# SF32LB57x register map
File version: 1.0
CPU: CM33 r0p1, little endian, MPU, FPU, 3 interrupt priority bits
Registers are 32-bit, read-write, reset 0x0 unless marked. A register's access mark holds for its fields unless they carry their own. Offsets are from the block's base; [hi:lo] are bit positions; {n}, {i} and the like mark numbered series.

## CAN1
Base 0x5000A000
Same registers: CAN2 0x5000E000
0x00 RBUF — Receive Buffer Registers
  [31:0] DATA
0x48 TBUF — Transmit Buffer Registers
  [31:0] DATA
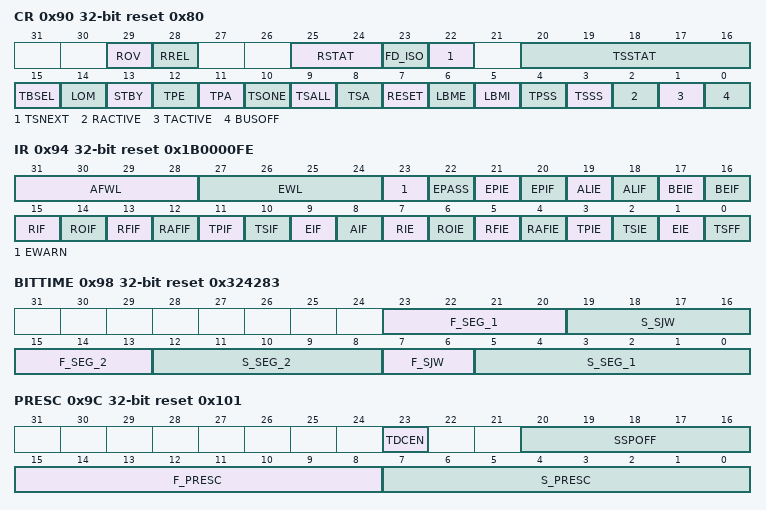
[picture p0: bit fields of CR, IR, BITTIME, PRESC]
0x90 CR reset 0x80 — Control Register
  [29] ROV — Receive buffer OVerflow 1 – Overflow. At least one message is lost. 0 – No Overflow. ROV is cleared by setting RREL=1.
  [28] RREL — Receive buffer RELease The host controller acknowledges the emptying of the actual RB slot. Afterwards the CAN-CTRL core points to the next RB slot. RSTAT gets updated. 1 – Release: The host has emptied the RB. 0 – No release
  [25:24] RSTAT — Receive buffer STATus 00 - empty 01 - > empty and lt almost full (AFWL) 10 - >= almost full (programmable threshold by AFWL) but not full and no overflow 11 - full (stays set in case of overflow – for overflow signaling see ROV)
  [23] FD_ISO — CAN FD ISO mode 0 - Bosch CAN FD (non-ISO) mode 1 - ISO CAN FD mode This bit is only writeable if RESET=1. ISO CAN FD mode has a different CRC initialization value and an additional stuff bit count. Both modes are incompatible and must not be mixed in one CAN network. This bit has no impact to CAN 2.0B.
  [22] TSNEXT — Transmit buffer Secondary NEXT 0 - no action 1 - STB slot filled, select next FIFO slot. After all frame bytes are written to the TBUF registers, the host controller has to set TSNEXT to signal that this slot has been filled. Then the CAN-CTRL core connects the TBUF registers to the next FIFO slot. Once a slot is marked as filled a transmission can be started using TSONE or TSALL. TSNEXT has to be set by the host controller and is automatically reset by the CAN-CTRL core immediately after it was set. Setting TSNEXT is only meaningful, if the STB is selected by TBSEL=1. If TBSEL=0 then TSNEXT is ignored and automatically cleared. It does not do any harm. If all slots of the STB are filled, TSNEXT stays set until a slot becomes free (chap. 3.6.7 ).
  [20:16] TSSTAT — Transmission Secondary STATus bits Number of filled message buffers (0 …16).
  [15] TBSEL — Transmit Buffer Select Selects the transmit buffer to be loaded with a message. Use the TBUF registers for access. TBSEL needs to be stable all the time the TBUF registers are written and when TSNEXT is set. 0 - PTB (high-priority buffer) 1 - STB (FIFO like)
  [14] LOM — Listen Only Mode 0 - Disabled 1 - Enabled LOM should not be enabled while a transmission is active. No transmission can be started if LOM is enabled.
  [13] STBY — Transceiver Standby Mode 0 - Disabled 1 - Enabled This register bit is connected to the output signal stby which can be used to control a standby mode of a transceiver. STBY cannot be set to 1 if TPE=1, TSONE=1 or TSALL=1. If the host sets STBY to 0 then the host needs to wait for the time required by the transceiver to start up before the host requests a new transmission.
  [12] TPE — Transmit Primary Enable 1 - Transmission enable of the message of the high-priority PTB 0 - No transmission for the PTB If TPE is set, the message from the PTB will be transmitted at the next possible transmit position. A started transmission from the STB will be completed before, but pending new messages are delayed until the PTB message has been transmitted. TPE stays set until the message has been transmitted successfully or it is aborted using TPA. Only, the host controller can set TPE. The host controller can set TPE to 1 but can not reset it to 0. This would only be possible using TPA and aborting the message. During the short time while the CAN-CTRL core resets the bit, it cannot be set by the host. The bit will be reset to the hardware reset value if RESET=1, BUSOFF=1, STBY=1 or LOM=1.
  [11] TPA — Transmit Primary Abort 1 – Aborts a transmission from TPB which has been requested by TPE=1 but not started yet. (The data bytes of the message remain in the PTB.) 0 – no abort The bit has to be set by the host controller and will be reset by CAN-CTRL. Setting TPA automatically de-asserts TPE. The host controller can set TPA to 1 but can not reset it to 0. During the short time while the CAN-CTRL core resets the bit, it cannot be set by the host. The bit will be reset to the hardware reset value if RESET=1 or BUSOFF=1. TPA should not be set simultaneously with TPE.
  [10] TSONE — Transmit Secondary ONE frame 1 – Transmission enable of the oldest message in the STB. The message format is stored in the IDE buffer which belongs to this message. The controller starts the transmission as soon as the bus becomes vacant and no request of the PTB (bit TPE) is pending. 0 – No transmission for the STB. TSONE stays set until the message has been transmitted successfully or it is aborted using TSA. Only the host controller can set TSONE. The host controller can set TSONE to 1 but can not reset it to 0. This would only be possible using TSA and aborting the message. During the short time while the CAN-CTRL core resets the bit, it cannot be set by the host. The bit will be reset to the hardware reset value if RESET=1, BUSOFF=1, STBY=1 or LOM=1.
  [9] TSALL — Transmit Secondary ALL frames 1 – Transmission enable of all messages in the STB. The message format is stored in the appropriate IDE buffers. The controller starts the transmission as soon as the bus becomes vacant and no request of the PTB (bit TPE) is pending. 0 – No transmission for the STB. TSALL stays set until all messages have been transmitted successfully or they are aborted using TSA. Only the host controller can set TSALL. The host controller can set TSALL to 1 but can not reset it to 0. This would only be possible using TSA and aborting the messages. During the short time while the CAN-CTRL core resets the bit, it cannot be set by the host. The bit will be reset to the hardware reset value if RESET=1, BUSOFF=1, STBY=1 or LOM=1. If during a transmission the STB is loaded with a new frame then the new frame will be transmitted too. In other words: a transmission initiated by TSALL is finished when the STB becomes empty. TSALL cannot ne set to 1 if STBY=1.
  [8] TSA — Transmit Secondary Abort 1 – Aborts a transmission from STB which has been requested but not started yet. For a TSONE transmission, only one frame is aborted while for a TSALL Transmission, all frames are aborted. One or all message slots will be released which updates TSSTAT. Because of the FIFO-like behavior of the STB all aborted messages are lost because they are not accessible any more. 0 – no abort The bit has to be set by the host controller and will be reset by CAN-CTRL. Setting TSA, automatically de-asserts TSONE or TSALL respectively. The host controller can set TSA to 1 but can not reset it to 0. The bit will be reset to the hardware reset value if RESET=1 or BUSOFF=1. TSA should not be set simultaneously with TSONE or TSALL.
  [7] RESET — RESET request bit 1 - The host controller performs a local reset of CAN-CTRL. 0 - no local reset of CAN-CTRL The node configuration (BITTIME_x, x_PRESC, acceptance code and mask) can only be modified if RESET=1. The CAN-CTRL core continuously listens on the bus. Wrong timings and acceptance filters may result in unpredictable and unwanted behavior. Therefore these parameters can only be changed if the protocol machine is reset and therefore disconnected from the bus. Bit RESET forces several components to a reset state. A detailed definition is given in chap. 3.6.10 . RESET is automatically set if the node enters “bus off” state (chap. 3.6.1 ). Note that a CAN node will participate in CAN communication after RESET is switched to 0 after 11 CAN bit times. This delay is required by the CAN standard. If RESET is set to 1 and immediately set to 0, then it takes some time until RESET can be read as 0 and becomes inactive. The reason is clock domain crossing from host to CAN clock domain. RESET is held active as long as needed depending on the relation between host and CAN clock.
  [6] LBME — Loop Back Mode, External 0 - Disabled 1 - Enabled LBME should not be enabled while a transmission is active.
  [5] LBMI — Loop Back Mode, Internal 0 - Disabled 1 - Enabled LBMI should not be enabled while a transmission is active.
  [4] TPSS — Transmission Primary Single Shot mode for PTB 0 - Disabled 1 - Enabled
  [3] TSSS — Transmission Secondary Single Shot mode for STB 0 - Disabled 1 - Enabled
  [2] RACTIVE — Reception ACTIVE (Receive Status bit) 1 - The controller is presently receiving data or a remote frame. 0 - No receive activity.
  [1] TACTIVE — Transmission ACTIVE (Transmit Status bit) 1 - The controller is presently transmitting data or a remote frame. 0 - No transmit activity.
  [0] BUSOFF — Bus Off (Bus Status bit) 1 - The controller status is “bus off”. 0 - The controller status is “bus on”.
0x94 IR reset 0x1B0000FE — Interrupt register
  [31:28] AFWL — receive buffer Almost Full Warning Limit AFWL defines the internal warning limit AFWL_i with nRB being the number of available RB slots.
  [27:24] EWL — Programmable Error Warning Limit = (EWL+1)*8. Possible Limit values: 8, 16, … 128. The value of EWL controls EIF. EWL needs to be transferred using CDC from host to CAN clock domain. During transfer EWL register bits are write-locked for the host for a few clocks until CDC is complete.
  [23] EWARN — Error WARNing limit reached 1 - One of the error counters RECNT or TECNT is equal or bigger than EWL 0 - The values in both counters are less than EWL.
  [22] EPASS — Error Passive mode active 0 - not active (node is error active) 1 - active (node is error passive)
  [21] EPIE — Error Passive Interrupt Enable
  [20] EPIF — Error Passive Interrupt Flag. EPIF will be activated if the error status changes from error active to error passive or vice versa and if this interrupt is enabled.
  [19] ALIE — Arbitration Lost Interrupt Enable
  [18] ALIF — Arbitration Lost Interrupt Flag
  [17] BEIE — Bus Error Interrupt Enable
  [16] BEIF — Bus Error Interrupt Flag
  [15] RIF — Receive Interrupt Flag 1 - Data or a remote frame has been received and is available in the receive buffer. 0 - No frame has been received.
  [14] ROIF — RB Overrun Interrupt Flag 1 - At least one received message has been overwritten in the RB. 0 - No RB overwritten. In case of an overrun both ROIF and RFIF will be set.
  [13] RFIF — RB Full Interrupt Flag 1 - All RBs are full. If no RB will be released until the next valid message is received, the oldest message will be lost. 0 - The RB FIFO is not full.
  [12] RAFIF — RB Almost Full Interrupt Flag 1 - number of filled RB slots >= AFWL_i 0 - number of filled RB slots lt AFWL_i
  [11] TPIF — Transmission Primary Interrupt Flag 1 - The requested transmission of the PTB has been successfully completed. 0 - No transmission of the PTB has been completed.
  [10] TSIF — Transmission Secondary Interrupt Flag 1 - The requested transmission of the STB has been successfully completed. 0 - No transmission of the STB has been completed successfully.
  [9] EIF — Error Interrupt Flag 1 - The border of the error warning limit has been crossed in either direction, or the BUSOFF bit has been changed in either direction. 0 - There has been no change.
  [8] AIF — Abort Interrupt Flag 1 - After setting TPA or TSA the appropriated message(s) have been aborted. It is recommended to not set both TPA and TSA simultaneously because both source AIF. 0 - No abort has been executed. The AIF does not have an associated enable register.
  [7] RIE — Receive Interrupt Enable 0 – Disabled, 1 – Enabled
  [6] ROIE — RB Overrun Interrupt Enable 0 – Disabled, 1 – Enabled
  [5] RFIE — RB Full Interrupt Enable 0 – Disabled, 1 – Enabled
  [4] RAFIE — RB Almost Full Interrupt Enable 0 – Disabled, 1 – Enabled
  [3] TPIE — Transmission Primary Interrupt Enable 0 – Disabled, 1 – Enabled
  [2] TSIE — Transmission Secondary Interrupt Enable 0 – Disabled, 1 – Enabled
  [1] EIE — Error Interrupt Enable 0 – Disabled, 1 – Enabled
  [0] TSFF — Transmit Secondary buffer Full Flag 1 - The STB is filled with the maximal count of messages. 0 - The STB is not filled with the maximal count of messages
0x98 BITTIME reset 0x324283
  [23:20] F_SEG_1 — Bit Timing Segment 1 (fast speed) The sample point will be set to tSeg_1=(Seg_1+2)*TQ after start of bit time. Seg_1=0 is meaningless and automatically treated as 1.
  [19:16] S_SJW — Synchronization Jump Width (slow speed) The Synchronization Jump Width tSJW=(SJW+1)*TQ is the maximum time for shortening or lengthening the Bit Time for resynchronization, where TQ is a time quanta.
  [15:13] F_SEG_2 — Bit Timing Segment 2 (fast speed) Time tSeg_2=(Seg_2+1)*TQ after the sample point. Seg_2=0 is meaningless and automatically treated as 1.
  [12:8] S_SEG_2 — Bit Timing Segment 2 (slow speed) Time tSeg_2=(Seg_2+1)*TQ after the sample point. Seg_2=0 is meaningless and automatically treated as 1.
  [7:6] F_SJW — Synchronization Jump Width (fast speed) The Synchronization Jump Width tSJW=(SJW+1)*TQ is the maximum time for shortening or lengthening the Bit Time for resynchronization, where TQ is a time quanta.
  [5:0] S_SEG_1 — Bit Timing Segment 1 (slow speed) The sample point will be set to tSeg_1=(Seg_1+2)*TQ after start of bit time. Seg_1=0 is meaningless and automatically treated as 1.
0x9C PRESC reset 0x101
  [23] TDCEN — Transmitter Delay Compensation ENable TDC will be activated during the data phase of a CAN FD frame if BRS is active if TDCEN=1.
  [20:16] SSPOFF — Secondary Sample Point OFFset The transmitter delay plus SSPOFF defines the time of the secondary sample point for TDC. SSPOFF is given as a number of TQ.
  [15:8] F_PRESC — Prescaler (fast speed) The prescaler divides the system clock to get the time quanta clock tq_clk. Valid range PRESC=[0x01, 0xff] results in divider values 2 to 256. PRESC=0 is forbidden and automatically treated as 1. (Necessary because the bit timing logic of this core requires it.)
  [7:0] S_PRESC — Prescaler (slow speed) The prescaler divides the system clock to get the time quanta clock tq_clk. Valid range PRESC=[0x01, 0xff] results in divider values 2 to 256. PRESC=0 is forbidden and automatically treated as 1. (Necessary because the bit timing logic of this core requires it.)
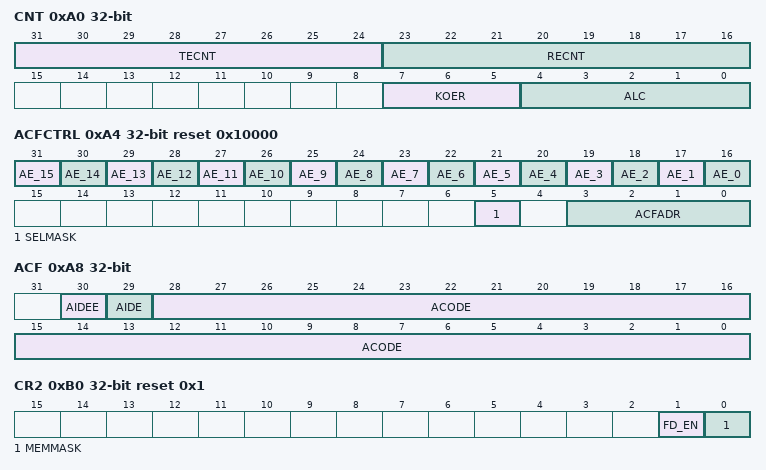
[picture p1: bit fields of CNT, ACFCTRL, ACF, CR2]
0xA0 CNT
  [31:24] TECNT — Transmit Error CouNT (number of errors during transmission) TECNT is incremented and decremented as defined in the CAN specification. TECNT does not overflow. TECNT signals 0xff = 255 as maximum value. See chap. 3.6.1 for more details about TECNT and the “bus off” state.
  [23:16] RECNT — Receive Error CouNT (number of errors during reception) RECNT is incremented and decremented as defined in the CAN specification. RECNT does not overflow. RECNT signals 0xff = 255 as maximum value. See chap. 3.6.1 for more details about RECNT and the “bus off” state.
  [7:5] KOER — Kind Of ERror (Error code) 000 - no error 001 - BIT ERROR 010 - FORM ERROR 011 - STUFF ERROR 100 - ACKNOWLEDGEMENT ERROR 101 - CRC ERROR 110 - OTHER ERROR (dominant bits after own error flag, received active Error Flag too long, dominant bit during Passive-Error-Flag after ACK error) 111 - not used KOER is reset after a successful transmission or reception of a frame.
  [4:0] ALC — Arbitration Lost Capture (bit position in the frame where the arbitration has been lost)
0xA4 ACFCTRL reset 0x10000
  [31] AE_15 — Acceptance filter Enable 1 - acceptance filter enabled 0 - acceptance filter disable Each acceptance filter (AMASK / ACODE) can be individually enabled or disabled. Only filter number 0 is enabled by default after hardware reset. Disabled filters reject a message. Only enabled filters can accept a message if the appropriate AMASK / ACODE configuration matches. To accept all messages one filter x has to be enabled by setting AE_x=1, AMASK_x=0xff and ACODE_x=0x00. This is the default configuration after hardware reset for filter x=0 while all other filters are disabled.
  [n+16] AE_{n} (n=0..14)
  [5] SELMASK — SELect acceptance MASK 0 - Registers ACF_x point to acceptance code 1 - Registers ACF_x point to acceptance mask. ACFADR selects one specific acceptance filter.
  [3:0] ACFADR — acceptance filter address ACFADR points to a specific acceptance filter. The selected filter is accessible using the registers ACF_x. Bit SELMASK selects between acceptance code and mask for the selected acceptance filter. A value of ACFADR>NR_OF_ACF-1 is meaningless and automatically treated as value NR_OF_ACF-1.
0xA8 ACF
  [30] AIDEE — Acceptance mask IDE bit check enable 1 - acceptance filter accepts either standard or extended as defined by AIDE 0 - acceptance filter accepts both standard or extended frames Only filter 0 is affected by the power-on reset. All other filters stay uninitialized.
  [29] AIDE — Acceptance mask IDE bit value If AIDEE=1 then: 1 - acceptance filter accepts only extended frames 0 - acceptance filter accepts only standard frames Only filter 0 is affected by the power-on reset. All other filters stay uninitialized.
  [28:0] ACODE — ACODE or AMASK selected by SELMASK. Acceptance CODE: 1 - ACC bit value to compare with ID bit of the received message 0 - ACC bit value to compare with ID bit of the received message ACODE_x(10:0) will be used for extended frames. ACODE_x(28:0) will be used for extended frames. Only filter 0 is affected by the power-on reset. All other filters stay uninitialized. Acceptance MASK: 1 - acceptance check for these bits of receive identifier disabled 0 - acceptance check for these bits of receive identifier enable AMASK_x(10:0) will be used for extended frames. AMASK_x(28:0) will be used for extended frames. Disabled bits result in accepting the message. Therefore the default configuration after reset for filter 0 accepts all messages. Only filter 0 is affected by the power-on reset. All other filters stay uninitialized.
0xAC VER reset 0x100 — Version Register
  [15:0] VERSION
0xB0 CR2 reset 0x1 — Control Register 2
  [1] FD_EN — CAN FD features can be enabled (1) or disabled (0) at runtime
  [0] MEMMASK — 0 - enable internal memory access. Must to cleared before CAN configuration 1 - disable internal memory access to save power
